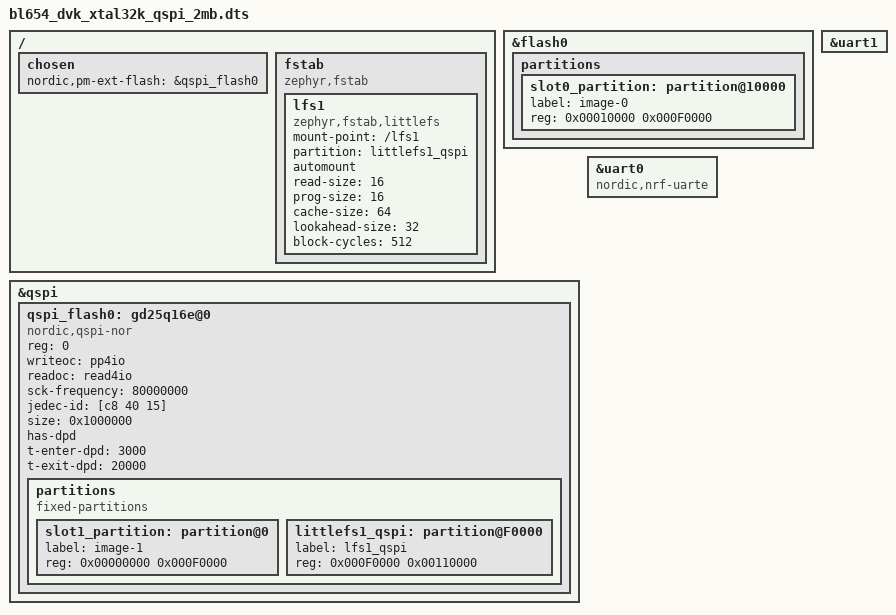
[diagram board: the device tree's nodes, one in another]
#include "bl654_dvk.dts"

/delete-node/ &slot0_partition;
/delete-node/ &slot1_partition;

/ {
	chosen {
		nordic,pm-ext-flash = &qspi_flash0;
	};

    fstab {
		compatible = "zephyr,fstab";
		lfs1: lfs1 {
			compatible = "zephyr,fstab,littlefs";
			mount-point = "/lfs1";
			partition = <&littlefs1_qspi>;
			automount;
			read-size = <16>;
			prog-size = <16>;
			cache-size = <64>;
			lookahead-size = <32>;
			block-cycles = <512>;
		};
	};
};

&flash0 {
	partitions {
		slot0_partition: partition@10000 {
			label = "image-0";
			reg = <0x00010000 0x000F0000>;
		};
	};
};

&qspi {
	qspi_flash0: gd25q16e@0 {
		compatible = "nordic,qspi-nor";
		reg = <0>;
		writeoc = "pp4io";
		readoc = "read4io";
		sck-frequency = <80000000>;
		jedec-id = [c8 40 15];
		size = <0x1000000>;
		has-dpd;
		t-enter-dpd = <3000>;
		t-exit-dpd = <20000>;

		partitions {
			compatible = "fixed-partitions";
			#address-cells = <1>;
			#size-cells = <1>;

			slot1_partition: partition@0 {
				label = "image-1";
				reg = <0x00000000 0x000F0000>;
			};

			littlefs1_qspi: partition@F0000 {
				label = "lfs1_qspi";
				reg = <0x000F0000 0x00110000>;
			};
		};
	};
};

&uart0 {
	compatible = "nordic,nrf-uarte";
};

&uart1 {
	status = "okay";
};
